VERSION ""

NS_ :

BS_:

BU_:

BO_ 257 M_DRIVER_MOTOR_CMD: 8.0 Vector__XXX
 SG_ S_DRIVER_MOTOR_VELOCITY : 0|32@1- (1,0) [-1500|1500] "RPM" Vector__XXX
 SG_ S_DRIVER_MOTOR_CURRENT : 32|32@1- (100,0) [-100|100] "PC" Vector__XXX

BO_ 258 M_DRIVER_POWER_CMD: 8.0 Vector__XXX
 SG_ S_DRIVER_POWER_OFFSET : 0|32@1+ (1,0) [0|0] "N/A" Vector__XXX
 SG_ S_DRIVER_BUS_CURRENT : 32|32@1- (100,0) [0|100] "PC" Vector__XXX

BO_ 512 M_DRIVE_ID: 8.0 Vector__XXX
 SG_ S_DRIVE_SERIAL : 0|32@1+ (1,0) [0|2147483647] "N/A" Vector__XXX
 SG_ S_DRIVE_ID : 32|32@1+ (1,0) [0|2147483647] "N/A" Vector__XXX

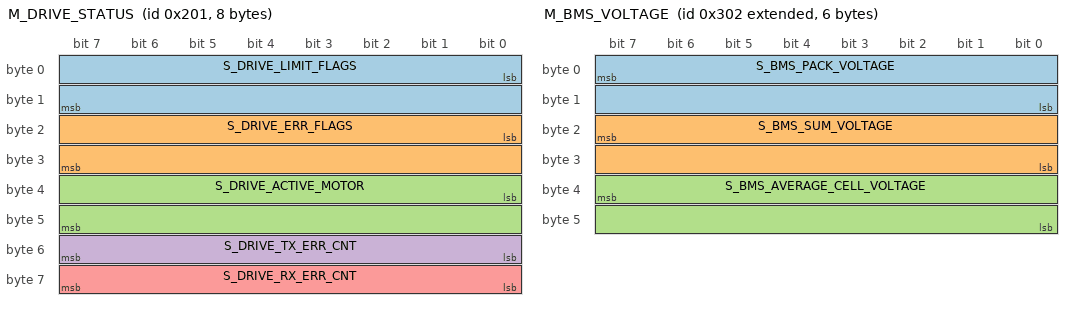
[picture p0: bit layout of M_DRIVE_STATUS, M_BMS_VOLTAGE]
BO_ 513 M_DRIVE_STATUS: 8.0 Vector__XXX
 SG_ S_DRIVE_LIMIT_FLAGS : 0|16@1+ (1,0) [0|15] "N/A" Vector__XXX
 SG_ S_DRIVE_ERR_FLAGS : 16|16@1+ (1,0) [0|15] "N/A" Vector__XXX
 SG_ S_DRIVE_ACTIVE_MOTOR : 32|16@1+ (1,0) [0|65532] "N/A" Vector__XXX
 SG_ S_DRIVE_TX_ERR_CNT : 48|8@1+ (1,0) [0|256] "N/A" Vector__XXX
 SG_ S_DRIVE_RX_ERR_CNT : 56|8@1+ (1,0) [0|256] "N/A" Vector__XXX

BO_ 514 M_DRIVE_BUS: 8.0 Vector__XXX
 SG_ S_DRIVE_BUS_VOLTAGE : 0|32@1- (1,0) [0|2147483647] "V" Vector__XXX
 SG_ S_DRIVE_BUS_CURRENT : 32|32@1- (1,0) [0|2147483647] "A" Vector__XXX

BO_ 515 M_DRIVE_VELOCITY: 8.0 Vector__XXX
 SG_ S_DRIVE_MOTOR_VELOCITY : 0|32@1- (1,0) [-2147483648|2147483647] "RPM" Vector__XXX
 SG_ S_DRIVE_VEHICLE_VELOCITY : 32|32@1- (3.6,0) [-2147483648|2147483647] "KM/H" Vector__XXX

BO_ 516 M_DRIVE_PHASE_CURRENT: 8.0 Vector__XXX
 SG_ S_DRIVE_PHASE_C_CURRENT : 0|32@1- (1,0) [0|2147483647] "ARMS" Vector__XXX
 SG_ S_DRIVE_PHASE_B_CURRENT : 32|32@1- (1,0) [0|2147483647] "ARMS" Vector__XXX

BO_ 519 M_DRIVE_BEMF: 8.0 Vector__XXX
 SG_ S_DRIVE_BEMFQ : 0|32@1- (1,0) [0|2147483647] "V" Vector__XXX
 SG_ S_DRIVE_BEMFD : 32|32@1- (1,0) [0|2147483647] "V" Vector__XXX

BO_ 520 M_DRIVE_15V: 8.0 Vector__XXX
 SG_ S_DRIVE_15V_OFFSET : 0|32@1- (1,0) [0|2147483647] "V" Vector__XXX
 SG_ S_DRIVE_15V : 32|32@1- (1,0) [0|2147483647] "V" Vector__XXX

BO_ 521 M_DRIVE_33V_19V: 8.0 Vector__XXX
 SG_ S_DRIVE_1_9V : 0|32@1- (1,0) [0|2147483647] "V" Vector__XXX
 SG_ S_DRIVE_3_3V : 32|32@1- (1,0) [0|2147483647] "V" Vector__XXX

BO_ 523 M_DRIVE_HEATSINK_MOTOR_TEMP: 8.0 Vector__XXX
 SG_ S_DRIVE_MOTOR_TEMP : 0|32@1- (1,0) [0|2147483647] "C" Vector__XXX
 SG_ S_DRIVE_HEATSINK_TEMP : 32|32@1- (1,0) [0|2147483647] "C" Vector__XXX

BO_ 524 M_DRIVE_DSP_TEMP: 4.0 Vector__XXX
 SG_ S_DRIVE_DSP_TEMP : 0|32@1- (1,0) [0|2147483647] "C" Vector__XXX

BO_ 526 M_DRIVE_ODOMETER_AMPHOUR: 8.0 Vector__XXX
 SG_ S_DRIVE_ODOMETER : 0|32@1- (1,0) [-2147483647|2147483647] "M" Vector__XXX
 SG_ S_DRIVE_DCBUS_AMPHOUR : 32|32@1- (1,0) [0|2147483647] "AH" Vector__XXX

BO_ 2147484416 M_BMS_STATUS: 6.0 Vector__XXX
 SG_ S_BMS_STATUS : 7|16@0+ (1,0) [0|65532] "N/A" Vector__XXX
 SG_ S_BMS_OSTICK : 23|32@0+ (1,0) [0|2147483647] "TICK" Vector__XXX

BO_ 2147484417 M_BMS_CURRENT: 4.0 Vector__XXX
 SG_ S_BMS_PACK_CURRENT : 7|32@0- (0.001,0) [-60|18] "A" Vector__XXX

BO_ 2147484418 M_BMS_VOLTAGE: 6.0 Vector__XXX
 SG_ S_BMS_PACK_VOLTAGE : 7|16@0+ (0.1,0) [800|1350] "V" Vector__XXX
 SG_ S_BMS_SUM_VOLTAGE : 23|16@0+ (0.1,0) [800|1350] "V" Vector__XXX
 SG_ S_BMS_AVERAGE_CELL_VOLTAGE : 39|16@0+ (1,0) [0|4200] "MV" Vector__XXX

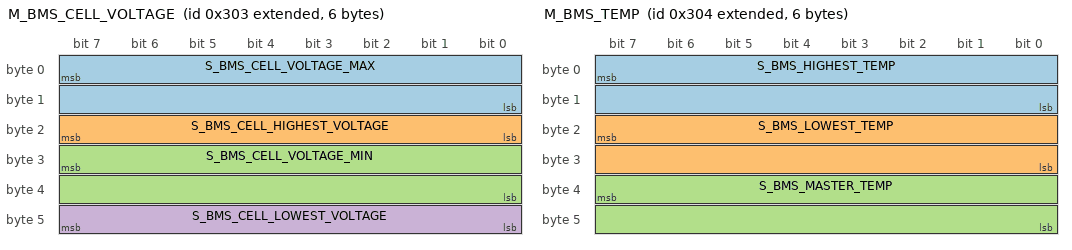
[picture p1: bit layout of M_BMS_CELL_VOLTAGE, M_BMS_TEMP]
BO_ 2147484419 M_BMS_CELL_VOLTAGE: 6.0 Vector__XXX
 SG_ S_BMS_CELL_VOLTAGE_MAX : 7|16@0+ (1,0) [0|4200] "MV" Vector__XXX
 SG_ S_BMS_CELL_HIGHEST_VOLTAGE : 23|8@0+ (1,0) [0|88] "NO" Vector__XXX
 SG_ S_BMS_CELL_VOLTAGE_MIN : 31|16@0+ (1,0) [0|4200] "MV" Vector__XXX
 SG_ S_BMS_CELL_LOWEST_VOLTAGE : 47|8@0+ (1,0) [0|88] "NO" Vector__XXX

BO_ 2147484420 M_BMS_TEMP: 6.0 Vector__XXX
 SG_ S_BMS_HIGHEST_TEMP : 7|16@0+ (0.1,0) [0|45] "C" Vector__XXX
 SG_ S_BMS_LOWEST_TEMP : 23|16@0+ (0.1,0) [0|45] "C" Vector__XXX
 SG_ S_BMS_MASTER_TEMP : 39|16@0+ (0.1,0) [0|45] "C" Vector__XXX

BO_ 2147484421 M_BMS_STATE: 2.0 Vector__XXX
 SG_ S_BMS_IO_STATE : 7|8@0+ (1,0) [0|255] "N/A" Vector__XXX
 SG_ S_BMS_SYSTEM_STATE : 15|8@0+ (1,0) [0|255] "N/A" Vector__XXX

BO_ 2147484422 M_BMS_ERRORS: 8.0 Vector__XXX
 SG_ S_BMS_ERRORS_FLAGS : 7|32@0+ (1,0) [0|2147483647] "N/A" Vector__XXX
 SG_ S_BMS_WARNING_FLAGS : 39|32@0+ (1,0) [0|2147483647] "N/A" Vector__XXX

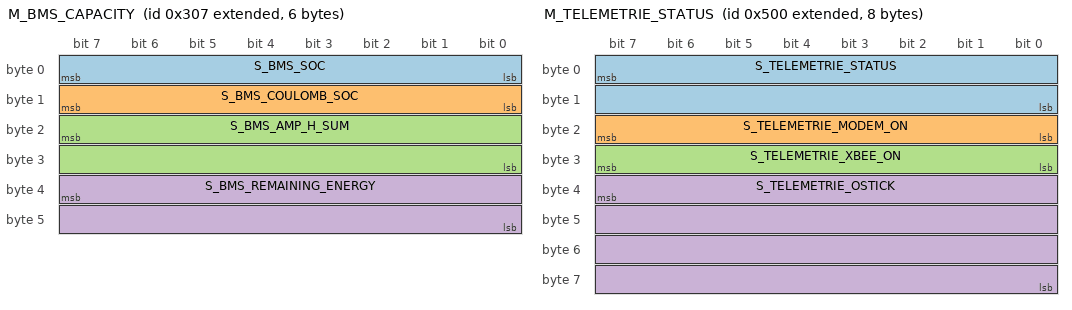
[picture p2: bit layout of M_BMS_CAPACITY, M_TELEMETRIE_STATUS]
BO_ 2147484423 M_BMS_CAPACITY: 6.0 Vector__XXX
 SG_ S_BMS_SOC : 7|8@0+ (1,0) [0|100] "PC" Vector__XXX
 SG_ S_BMS_COULOMB_SOC : 15|8@0+ (1,0) [0|100] "PC" Vector__XXX
 SG_ S_BMS_AMP_H_SUM : 23|16@0+ (1,0) [0|65536] "N/A" Vector__XXX
 SG_ S_BMS_REMAINING_ENERGY : 39|16@0+ (1,0) [0|65532] "WH" Vector__XXX

BO_ 2147484424 M_BMS_DATA: 8.0 Vector__XXX
 SG_ S_BMS_SLAVE_COMM_WARNINGS : 7|32@0+ (1,0) [0|2147483647] "N/A" Vector__XXX
 SG_ S_BMS_MASTER_POWER_UP_TIME : 39|32@0+ (1,0) [0|2147483647] "N/A" Vector__XXX

BO_ 2147484672 M_DASHBOARD_STATUS: 6.0 Vector__XXX
 SG_ S_DASHBOARD_STATUS : 7|16@0+ (1,0) [0|65532] "N/A" Vector__XXX
 SG_ S_DASHBOARD_OSTICK : 23|32@0+ (1,0) [0|2147483647] "TICK" Vector__XXX

BO_ 2147484673 M_DASHBOARD_CTRL: 2.0 Vector__XXX
 SG_ S_DASHBOARD_BREAK : 7|8@0+ (1,0) [0|1] "N/A" Vector__XXX
 SG_ S_DASHBOARD_BUTTON : 15|8@0+ (1,0) [0|255] "N/A" Vector__XXX

BO_ 2147484928 M_TELEMETRIE_STATUS: 8.0 Vector__XXX
 SG_ S_TELEMETRIE_STATUS : 7|16@0+ (1,0) [0|65532] "N/A" Vector__XXX
 SG_ S_TELEMETRIE_MODEM_ON : 23|8@0+ (1,0) [0|1] "N/A" Vector__XXX
 SG_ S_TELEMETRIE_XBEE_ON : 31|8@0+ (1,0) [0|1] "N/A" Vector__XXX
 SG_ S_TELEMETRIE_OSTICK : 39|32@0+ (1,0) [-2147483647|2147483647] "TICK" Vector__XXX

BO_ 2147485184 M_VOLANT_STATUS: 6.0 Vector__XXX
 SG_ S_VOLANT_STATUS : 7|16@0+ (1,0) [0|65532] "N/A" Vector__XXX
 SG_ S_VOLANT_OSTICK : 23|32@0+ (1,0) [0|2147483647] "TICK" Vector__XXX

BO_ 2147485185 M_VOLANT_CTRL: 3.0 Vector__XXX
 SG_ S_VOLANT_OPMODE : 7|8@0+ (1,0) [0|255] "N/A" Vector__XXX
 SG_ S_VOLANT_BUTTON : 15|16@0+ (1,0) [0|65532] "N/A" Vector__XXX

BO_ 2147485440 M_POWERSUPPLY_STATUS: 6.0 Vector__XXX
 SG_ S_POWERSUPPLY_STATUS : 7|16@0+ (0.001,0) [0|65532] "N/A" Vector__XXX
 SG_ S_POWERSUPPLY_OSTICK : 23|32@0+ (0.001,0) [0|65532] "TICK" Vector__XXX

BO_ 2147485441 M_POWERSUPPLY_CAN: 4.0 Vector__XXX
 SG_ S_POWERSUPPLY_12V_CAN_COURANT : 7|16@0- (0.001,0) [-2147483647|2147483647] "A" Vector__XXX
 SG_ S_POWERSUPPLY_12V_CAN_VOLTAGE : 23|16@0- (0.001,0) [1100|1500] "MV" Vector__XXX

BO_ 2147485442 M_POWERSUPPLY_HP: 4.0 Vector__XXX
 SG_ S_POWERSUPPLY_12V_HP_COURANT : 7|16@0- (0.001,0) [-2147483647|2147483647] "A" Vector__XXX
 SG_ S_POWERSUPPLY_12V_HP_VOLTAGE : 23|16@0- (0.001,0) [1000|1500] "MV" Vector__XXX

BO_ 2147485443 M_POWERSUPPLY_AUX: 4.0 Vector__XXX
 SG_ S_POWERSUPPLY_12V_AUX_COURANT : 7|16@0- (0.001,0) [-2147483647|2147483647] "A" Vector__XXX
 SG_ S_POWERSUPPLY_12V_AUX_VOLTAGE : 23|16@0- (0.001,0) [1100|1500] "MV" Vector__XXX

BO_ 2147485696 M_IGNITION_ID: 1.0 Vector__XXX
 SG_ S_IGNITION_STATUS1 : 7|8@0+ (1,0) [0|255] "N/A" Vector__XXX

BO_ 2147485952 M_FLASHER_TOP: 6.0 Vector__XXX
 SG_ S_FLASHER_1_STATUS : 7|16@0+ (1,0) [0|65532] "N/A" Vector__XXX
 SG_ S_FLASHER_1_OSTICK : 23|32@0+ (1,0) [0|2147483647] "TICK" Vector__XXX

BO_ 2147485953 M_FLASHER_BOT: 6.0 Vector__XXX
 SG_ S_FLASHER_2_STATUS : 7|16@0+ (1,0) [0|65532] "N/A" Vector__XXX
 SG_ S_FLASHER_2_OSTICK : 23|32@0+ (1,0) [0|2147483647] "TICK" Vector__XXX

BO_ 2147487744 M_MUPPET_STATUS_MPPT1: 2.0 Vector__XXX
 SG_ S_MUPPET_FLAG_MPPT1 : 7|8@0+ (1,0) [0|255] "FLAG" Vector__XXX
 SG_ S_MUPPET_TEMP_MPPT1 : 15|8@0+ (1,0) [0|98] "C" Vector__XXX

BO_ 2147487745 M_MUPPET_I_MPPT1: 8.0 Vector__XXX
 SG_ S_MUPPET_IIN_MPPT1 : 7|32@0- (1,0) [0|6] "A" Vector__XXX
 SG_ S_MUPPET_IOUT_MPPT1 : 39|32@0- (1,0) [0|6] "A" Vector__XXX

BO_ 2147487746 M_MUPPET_U_MPPT1: 8.0 Vector__XXX
 SG_ S_MUPPET_UIN_MPPT1 : 7|32@0- (1,0) [60|90] "V" Vector__XXX
 SG_ S_MUPPET_UOUT_MPPT1 : 39|32@0- (1,0) [80|140] "V" Vector__XXX

BO_ 2147487747 M_MUPPET_STATUS_MPPT2: 2.0 Vector__XXX
 SG_ S_MUPPET_FLAG_MPPT2 : 7|8@0+ (1,0) [0|255] "FLAG" Vector__XXX
 SG_ S_MUPPET_TEMP_MPPT2 : 15|8@0+ (1,0) [0|98] "C" Vector__XXX

BO_ 2147487748 M_MUPPET_I_MPPT2: 8.0 Vector__XXX
 SG_ S_MUPPET_IIN_MPPT2 : 7|32@0- (1,0) [0|6] "A" Vector__XXX
 SG_ S_MUPPET_IOUT_MPPT2 : 39|32@0- (1,0) [0|6] "A" Vector__XXX

BO_ 2147487749 M_MUPPET_U_MPPT2: 8.0 Vector__XXX
 SG_ S_MUPPET_UIN_MPPT2 : 7|32@0- (1,0) [60|90] "V" Vector__XXX
 SG_ S_MUPPET_UOUT_MPPT2 : 39|32@0- (1,0) [80|140] "V" Vector__XXX

BO_ 2147487750 M_MUPPET_STATUS_MPPT3: 2.0 Vector__XXX
 SG_ S_MUPPET_FLAG_MPPT3 : 7|8@0+ (1,0) [0|255] "FLAG" Vector__XXX
 SG_ S_MUPPET_TEMP_MPPT3 : 15|8@0+ (1,0) [0|98] "C" Vector__XXX

BO_ 2147487751 M_MUPPET_I_MPPT3: 8.0 Vector__XXX
 SG_ S_MUPPET_IIN_MPPT3 : 7|32@0- (1,0) [0|6] "A" Vector__XXX
 SG_ S_MUPPET_IOUT_MPPT3 : 39|32@0- (1,0) [0|6] "A" Vector__XXX

BO_ 2147487752 M_MUPPET_U_MPPT3: 8.0 Vector__XXX
 SG_ S_MUPPET_UIN_MPPT3 : 7|32@0- (1,0) [60|90] "V" Vector__XXX
 SG_ S_MUPPET_UOUT_MPPT3 : 39|32@0- (1,0) [80|140] "V" Vector__XXX

BO_ 2147487753 M_MUPPET_STATUS_MPPT4: 2.0 Vector__XXX
 SG_ S_MUPPET_FLAG_MPPT4 : 7|8@0+ (1,0) [0|255] "FLAG" Vector__XXX
 SG_ S_MUPPET_TEMP_MPPT4 : 15|8@0+ (1,0) [0|98] "C" Vector__XXX

BO_ 2147487754 M_MUPPET_I_MPPT4: 8.0 Vector__XXX
 SG_ S_MUPPET_IIN_MPPT4 : 7|32@0- (1,0) [0|6] "A" Vector__XXX
 SG_ S_MUPPET_IOUT_MPPT4 : 39|32@0- (1,0) [0|6] "A" Vector__XXX

BO_ 2147487755 M_MUPPET_U_MPPT4: 8.0 Vector__XXX
 SG_ S_MUPPET_UIN_MPPT4 : 7|32@0- (1,0) [60|90] "V" Vector__XXX
 SG_ S_MUPPET_UOUT_MPPT4 : 39|32@0- (1,0) [80|140] "V" Vector__XXX

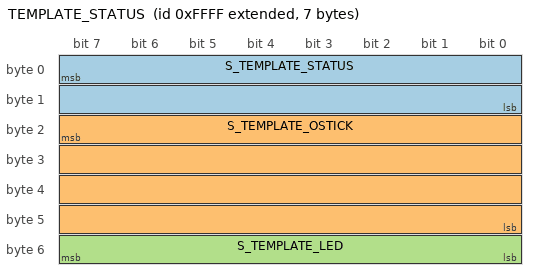
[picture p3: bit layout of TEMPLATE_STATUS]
BO_ 2147549183 TEMPLATE_STATUS: 7.0 Vector__XXX
 SG_ S_TEMPLATE_STATUS : 7|16@0+ (1,0) [0|65532] "N/A" Vector__XXX
 SG_ S_TEMPLATE_OSTICK : 23|32@0+ (1,0) [0|65532] "N/A" Vector__XXX
 SG_ S_TEMPLATE_LED : 55|8@0+ (1,0) [0|65532] "N/A" Vector__XXX

SIG_VALTYPE_ 257 S_DRIVER_MOTOR_VELOCITY : 1;
SIG_VALTYPE_ 257 S_DRIVER_MOTOR_CURRENT : 1;
SIG_VALTYPE_ 258 S_DRIVER_BUS_CURRENT : 1;
SIG_VALTYPE_ 514 S_DRIVE_BUS_VOLTAGE : 1;
SIG_VALTYPE_ 514 S_DRIVE_BUS_CURRENT : 1;
SIG_VALTYPE_ 515 S_DRIVE_MOTOR_VELOCITY : 1;
SIG_VALTYPE_ 515 S_DRIVE_VEHICLE_VELOCITY : 1;
SIG_VALTYPE_ 516 S_DRIVE_PHASE_C_CURRENT : 1;
SIG_VALTYPE_ 516 S_DRIVE_PHASE_B_CURRENT : 1;
SIG_VALTYPE_ 519 S_DRIVE_BEMFQ : 1;
SIG_VALTYPE_ 519 S_DRIVE_BEMFD : 1;
SIG_VALTYPE_ 520 S_DRIVE_15V_OFFSET : 1;
SIG_VALTYPE_ 520 S_DRIVE_15V : 1;
SIG_VALTYPE_ 521 S_DRIVE_1_9V : 1;
SIG_VALTYPE_ 521 S_DRIVE_3_3V : 1;
SIG_VALTYPE_ 523 S_DRIVE_MOTOR_TEMP : 1;
SIG_VALTYPE_ 523 S_DRIVE_HEATSINK_TEMP : 1;
SIG_VALTYPE_ 524 S_DRIVE_DSP_TEMP : 1;
SIG_VALTYPE_ 526 S_DRIVE_ODOMETER : 1;
SIG_VALTYPE_ 526 S_DRIVE_DCBUS_AMPHOUR : 1;
SIG_VALTYPE_ 2147487745 S_MUPPET_IIN_MPPT1 : 1;
SIG_VALTYPE_ 2147487745 S_MUPPET_IOUT_MPPT1 : 1;
SIG_VALTYPE_ 2147487746 S_MUPPET_UIN_MPPT1 : 1;
SIG_VALTYPE_ 2147487746 S_MUPPET_UOUT_MPPT1 : 1;
SIG_VALTYPE_ 2147487748 S_MUPPET_IIN_MPPT2 : 1;
SIG_VALTYPE_ 2147487748 S_MUPPET_IOUT_MPPT2 : 1;
SIG_VALTYPE_ 2147487749 S_MUPPET_UIN_MPPT2 : 1;
SIG_VALTYPE_ 2147487749 S_MUPPET_UOUT_MPPT2 : 1;
SIG_VALTYPE_ 2147487751 S_MUPPET_IIN_MPPT3 : 1;
SIG_VALTYPE_ 2147487751 S_MUPPET_IOUT_MPPT3 : 1;
SIG_VALTYPE_ 2147487752 S_MUPPET_UIN_MPPT3 : 1;
SIG_VALTYPE_ 2147487752 S_MUPPET_UOUT_MPPT3 : 1;
SIG_VALTYPE_ 2147487754 S_MUPPET_IIN_MPPT4 : 1;
SIG_VALTYPE_ 2147487754 S_MUPPET_IOUT_MPPT4 : 1;
SIG_VALTYPE_ 2147487755 S_MUPPET_UIN_MPPT4 : 1;
SIG_VALTYPE_ 2147487755 S_MUPPET_UOUT_MPPT4 : 1;
